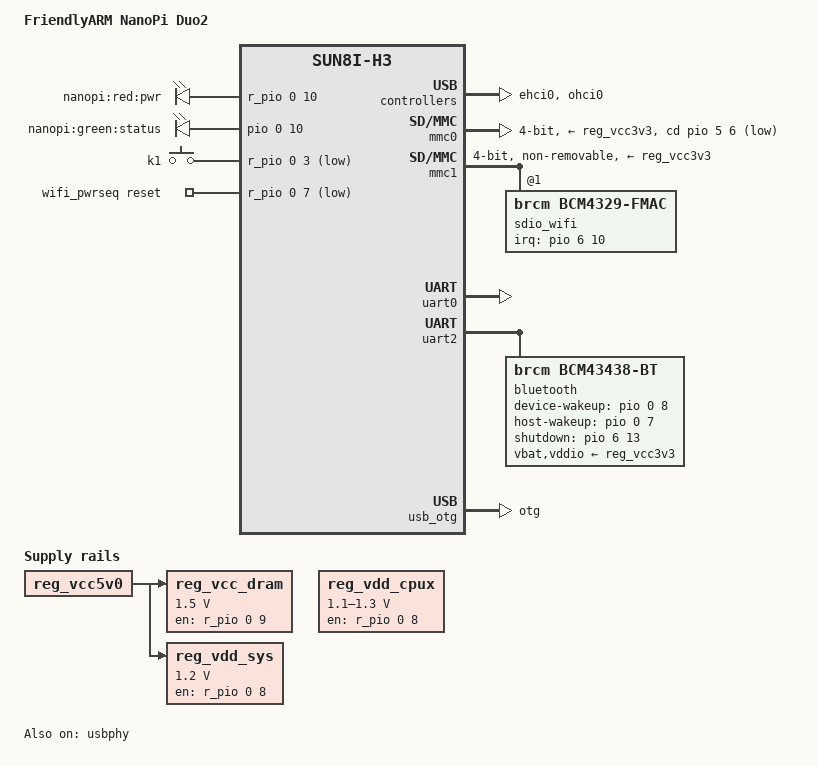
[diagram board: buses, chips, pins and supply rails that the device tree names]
/dts-v1/;
#include "sun8i-h3.dtsi"
#include "sunxi-common-regulators.dtsi"
#include <dt-bindings/gpio/gpio.h>
#include <dt-bindings/input/input.h>
/ {
	model = "FriendlyARM NanoPi Duo2";
	compatible = "friendlyarm,nanopi-duo2", "allwinner,sun8i-h3";
	aliases {
		serial0 = &uart0;
	};
	chosen {
		stdout-path = "serial0:115200n8";
	};
	leds {
		compatible = "gpio-leds";
		led-0 {
			label = "nanopi:red:pwr";
			gpios = <&r_pio 0 10 GPIO_ACTIVE_HIGH>;  
			default-state = "on";
		};
		led-1 {
			label = "nanopi:green:status";
			gpios = <&pio 0 10 GPIO_ACTIVE_HIGH>;  
		};
	};
	gpio-keys {
		compatible = "gpio-keys";
		key-0 {
			label = "k1";
			linux,code = <BTN_0>;
			gpios = <&r_pio 0 3 GPIO_ACTIVE_LOW>;  
		};
	};
	reg_vdd_cpux: vdd-cpux-regulator {
		compatible = "regulator-gpio";
		regulator-name = "vdd-cpux";
		regulator-min-microvolt = <1100000>;
		regulator-max-microvolt = <1300000>;
		regulator-always-on;
		regulator-boot-on;
		regulator-ramp-delay = <50>;  
		enable-active-high;
		enable-gpios = <&r_pio 0 8 GPIO_ACTIVE_HIGH>;  
		gpios = <&r_pio 0 6 GPIO_ACTIVE_HIGH>;  
		gpios-states = <0x1>;
		states = <1100000 0>, <1300000 1>;
	};
	reg_vcc_dram: vcc-dram {
		compatible = "regulator-fixed";
		regulator-name = "vcc-dram";
		regulator-min-microvolt = <1500000>;
		regulator-max-microvolt = <1500000>;
		regulator-always-on;
		regulator-boot-on;
		enable-active-high;
		gpio = <&r_pio 0 9 GPIO_ACTIVE_HIGH>;  
		vin-supply = <&reg_vcc5v0>;
        };
	reg_vdd_sys: vdd-sys {
		compatible = "regulator-fixed";
		regulator-name = "vdd-sys";
		regulator-min-microvolt = <1200000>;
		regulator-max-microvolt = <1200000>;
		regulator-always-on;
		regulator-boot-on;
		enable-active-high;
		gpio = <&r_pio 0 8 GPIO_ACTIVE_HIGH>;  
		vin-supply = <&reg_vcc5v0>;
        };
	wifi_pwrseq: wifi_pwrseq {
		compatible = "mmc-pwrseq-simple";
		reset-gpios = <&r_pio 0 7 GPIO_ACTIVE_LOW>;  
		clocks = <&rtc CLK_OSC32K_FANOUT>;
		clock-names = "ext_clock";
	};
};
&cpu0 {
	cpu-supply = <&reg_vdd_cpux>;
};
&ehci0 {
	status = "okay";
};
&mmc0 {
	bus-width = <4>;
	cd-gpios = <&pio 5 6 GPIO_ACTIVE_LOW>;  
	status = "okay";
	vmmc-supply = <&reg_vcc3v3>;
};
&mmc1 {
	vmmc-supply = <&reg_vcc3v3>;
	vqmmc-supply = <&reg_vcc3v3>;
	mmc-pwrseq = <&wifi_pwrseq>;
	bus-width = <4>;
	non-removable;
	status = "okay";
	sdio_wifi: sdio_wifi@1 {
		reg = <1>;
		compatible = "brcm,bcm4329-fmac";
		interrupt-parent = <&pio>;
		interrupts = <6 10 IRQ_TYPE_LEVEL_LOW>;  
		interrupt-names = "host-wake";
	};
};
&ohci0 {
	status = "okay";
};
&reg_usb0_vbus {
	gpio = <&r_pio 0 2 GPIO_ACTIVE_HIGH>;  
	status = "okay";
};
&uart0 {
	pinctrl-names = "default";
	pinctrl-0 = <&uart0_pa_pins>;
	status = "okay";
};
&uart2 {
	pinctrl-names = "default";
	pinctrl-0 = <&uart2_pins>, <&uart2_rts_cts_pins>;
	uart-has-rtscts;
	status = "okay";
	bluetooth {
		compatible = "brcm,bcm43438-bt";
		clocks = <&rtc CLK_OSC32K_FANOUT>;
		clock-names = "lpo";
		vbat-supply = <&reg_vcc3v3>;
		vddio-supply = <&reg_vcc3v3>;
		device-wakeup-gpios = <&pio 0 8 GPIO_ACTIVE_HIGH>;  
		host-wakeup-gpios = <&pio 0 7 GPIO_ACTIVE_HIGH>;  
		shutdown-gpios = <&pio 6 13 GPIO_ACTIVE_HIGH>;  
	};
};
&usb_otg {
	status = "okay";
	dr_mode = "otg";
};
&usbphy {
	usb0_id_det-gpios = <&pio 6 12 GPIO_ACTIVE_HIGH>;  
	usb0_vbus-supply = <&reg_usb0_vbus>;
	status = "okay";
};
